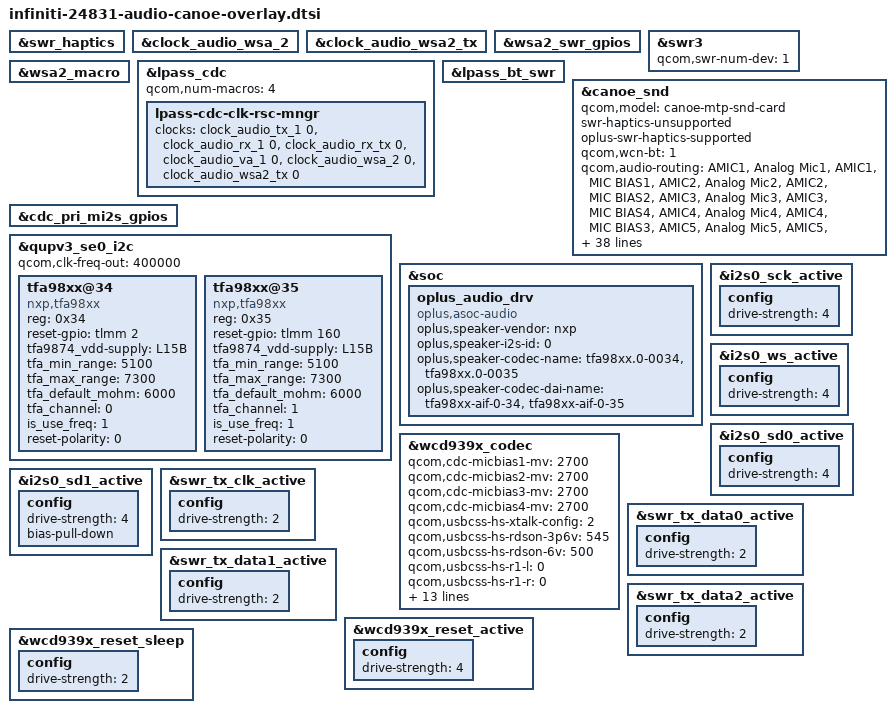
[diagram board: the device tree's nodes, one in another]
&swr_haptics {
	status = "ok";
};

&clock_audio_wsa_2 {
	status = "ok";
};

&clock_audio_wsa2_tx {
	status = "ok";
};

&wsa2_swr_gpios {
	status = "ok";
};

&swr3 {
	qcom,swr-num-dev = <1>; // only haptics connected
};

&wsa2_macro {
	status = "ok";
};

&lpass_cdc {
	qcom,num-macros = <4>;
	lpass-cdc-clk-rsc-mngr {
		clock-names = "tx_core_clk", "rx_core_clk", "rx_tx_core_clk", "va_core_clk",
				"wsa2_core_clk", "wsa2_tx_core_clk";
		clocks = <&clock_audio_tx_1 0>, <&clock_audio_rx_1 0>,
			<&clock_audio_rx_tx 0>, <&clock_audio_va_1 0>,
			<&clock_audio_wsa_2 0>, <&clock_audio_wsa2_tx 0>;
	};
};

&lpass_bt_swr {
        status = "ok";
};

&canoe_snd {
	qcom,model = "canoe-mtp-snd-card";
	swr-haptics-unsupported;
	oplus-swr-haptics-supported; // use oplus haptics
	qcom,wcn-bt = <1>;
	qcom,audio-routing =
		"AMIC1", "Analog Mic1",
		"AMIC1", "MIC BIAS1",
		"AMIC2", "Analog Mic2",
		"AMIC2", "MIC BIAS2",
		"AMIC3", "Analog Mic3",
		"AMIC3", "MIC BIAS4",
		"AMIC4", "Analog Mic4",
		"AMIC4", "MIC BIAS3",
		"AMIC5", "Analog Mic5",
		"AMIC5", "MIC BIAS1",
		"VA AMIC1", "Analog Mic1",
		"VA AMIC1", "VA MIC BIAS1",
		"VA AMIC2", "Analog Mic2",
		"VA AMIC2", "VA MIC BIAS2",
		"VA AMIC3", "Analog Mic3",
		"VA AMIC3", "VA MIC BIAS4",
		"VA AMIC4", "Analog Mic4",
		"VA AMIC4", "VA MIC BIAS3",
		"VA AMIC5", "Analog Mic5",
		"VA AMIC5", "VA MIC BIAS1",
		"TX DMIC0", "Digital Mic0",
		"TX DMIC0", "MIC BIAS1",
		"TX DMIC1", "Digital Mic1",
		"TX DMIC1", "MIC BIAS1",
		"TX DMIC2", "Digital Mic2",
		"TX DMIC2", "MIC BIAS3",
		"TX DMIC3", "Digital Mic3",
		"TX DMIC3", "MIC BIAS3",
		"IN1_HPHL", "HPHL_OUT",
		"IN2_HPHR", "HPHR_OUT",
		"IN3_EAR", "AUX_OUT",
		"HAP_IN", "WSA2_HAPT OUT", // haptics connect to wsa2
		"RX_TX DEC0_INP", "TX DEC0 MUX",
		"RX_TX DEC1_INP", "TX DEC1 MUX",
		"RX_TX DEC2_INP", "TX DEC2 MUX",
		"RX_TX DEC3_INP", "TX DEC3 MUX",
		"TX SWR_INPUT", "WCD_TX_OUTPUT",
		"VA SWR_INPUT", "VA_SWR_CLK",
		"VA SWR_INPUT", "WCD_TX_OUTPUT",
		"VA_AIF1 CAP", "VA_SWR_CLK",
		"VA_AIF2 CAP", "VA_SWR_CLK",
		"VA_AIF3 CAP", "VA_SWR_CLK",
		"VA DMIC0", "Digital Mic0",
		"VA DMIC1", "Digital Mic1",
		"VA DMIC2", "Digital Mic2",
		"VA DMIC3", "Digital Mic3",
		"VA DMIC0", "VA MIC BIAS1",
		"VA DMIC1", "VA MIC BIAS1",
		"VA DMIC2", "VA MIC BIAS3",
		"VA DMIC3", "VA MIC BIAS3";

	qcom,mi2s-audio-intf = <1>;
	qcom,tdm-audio-intf = <0>;
	qcom,pri-mi2s-gpios = <&cdc_pri_mi2s_gpios>;

	qcom,msm-mbhc-usbc-audio-supported = <1>;
	qcom,msm-mbhc-hs-mic-max-threshold-mv = <2600>;
	qcom,msm-mbhc-hs-mic-min-threshold-mv = <112>; /* 75*2700/1800 */
	qcom,msm-mbhc-hphl-swh = <0>;
	qcom,msm-mbhc-gnd-swh = <0>;
	oplus,mbhc-headset-micbias-alwayon = <1>;
	oplus,mbhc-check-cross-conn = <1>;
	qcom,wcd-disable-legacy-surge;
	pinctrl-names = "det_gpio_active";
	pinctrl-0 = <&hp_det_1p2_active &hp_det_1p8_active>;
};

&cdc_pri_mi2s_gpios {
	status = "ok";
};

&qupv3_se0_i2c {
	status = "ok";
	qcom,clk-freq-out = <400000>;
	tfa98xx@34 {
		compatible = "nxp,tfa98xx";
		reg = <0x34>;
		reset-gpio = <&tlmm 2 0x00>;
		tfa9874_vdd-supply = <&L15B>;
		tfa_min_range = <5100>;
		tfa_max_range = <7300>;
		tfa_default_mohm = <6000>;
		tfa_channel = <0>;
		is_use_freq = <1>;
		reset-polarity = <0>;
		status = "ok";
	};
	tfa98xx@35 {
		compatible = "nxp,tfa98xx";
		reg = <0x35>;
		reset-gpio = <&tlmm 160 0x00>;
		tfa9874_vdd-supply = <&L15B>;
		tfa_min_range = <5100>;
		tfa_max_range = <7300>;
		tfa_default_mohm = <6000>;
		tfa_channel = <1>;
		is_use_freq = <1>;
		reset-polarity = <0>;
		status = "ok";
	};
};

&soc {
	oplus_audio_drv: oplus_audio_drv {
		compatible = "oplus,asoc-audio";
		//for nxp speaker
		oplus,speaker-vendor = "nxp";
		oplus,speaker-i2s-id = <0>;
		oplus,speaker-codec-name = "tfa98xx.0-0034", "tfa98xx.0-0035";
		oplus,speaker-codec-dai-name = "tfa98xx-aif-0-34", "tfa98xx-aif-0-35";
	};
};

&wcd939x_codec {
	qcom,cdc-micbias1-mv = <2700>;
	qcom,cdc-micbias2-mv = <2700>;
	qcom,cdc-micbias3-mv = <2700>;
	qcom,cdc-micbias4-mv = <2700>;

	/* 0 for digital crosstalk disabled,
	 * 1 for digital crosstalk with local sensed a-xtalk enabled, and
	 * 2 for digital crosstalk with remote sensed a-xtalk enabled.
	 */
	qcom,usbcss-hs-xtalk-config = <2>;
	qcom,usbcss-hs-rdson-3p6v = <545>;
	qcom,usbcss-hs-rdson-6v = <500>;
	qcom,usbcss-hs-r1-l = <0>;
	qcom,usbcss-hs-r1-r = <0>;
	qcom,usbcss-hs-r3-l = <1>;
	qcom,usbcss-hs-r3-r = <1>;
	qcom,usbcss-hs-r4-sbu1 = <530>;
	qcom,usbcss-hs-r4-sbu2 = <530>;
	qcom,usbcss-hs-r5-sbu1 = <5>;
	qcom,usbcss-hs-r5-sbu2 = <5>;
	qcom,usbcss-hs-r6-sbu1 = <1>;
	qcom,usbcss-hs-r6-sbu2 = <1>;
	qcom,usbcss-hs-r7-sbu1 = <5>;
	qcom,usbcss-hs-r7-sbu2 = <5>;
	qcom,usbcss-hs-rcom-margin = <500>;
	qcom,usbcss-hs-diff-slope = <9898>;
	qcom,usbcss-hs-lin-k-aud = <13>;
};

&i2s0_sck_active {
	config {
		drive-strength = <4>;   /* 4 mA */
	};
};

&i2s0_ws_active {
	config {
		drive-strength = <4>;   /* 4 mA */
	};
};

&i2s0_sd0_active {
	config {
		drive-strength = <4>;   /* 4 mA */
	};
};

&i2s0_sd1_active {
	config {
		drive-strength = <4>;   /* 4 mA */
		bias-pull-down;         /* PULL DOWN */
	};
};

&swr_tx_clk_active {
	config {
		drive-strength = <2>;   /* 2 mA */
	};
};

&swr_tx_data0_active {
	config {
		drive-strength = <2>;   /* 2 mA */
	};
};

&swr_tx_data1_active {
	config {
		drive-strength = <2>;   /* 2 mA */
	};
};

&swr_tx_data2_active {
	config {
		drive-strength = <2>;   /* 2 mA */
	};
};

&wcd939x_reset_active {
	config {
		drive-strength = <4>;   /* 4 mA */
	};
};

&wcd939x_reset_sleep {
	config {
		drive-strength = <2>;   /* 2 mA */
	};
};
